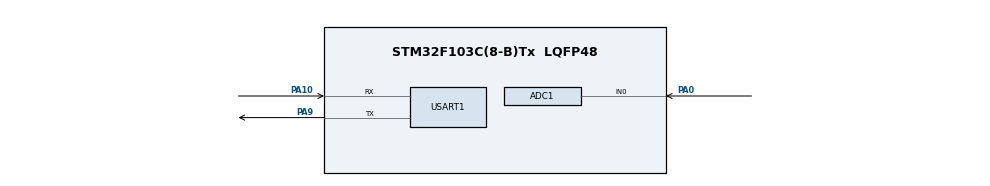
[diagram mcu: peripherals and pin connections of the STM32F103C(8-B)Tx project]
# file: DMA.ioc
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ADC1.Channel-0\#ChannelRegularConversion=ADC_CHANNEL_0
ADC1.ExternalTrigConv=ADC_EXTERNALTRIGCONV_T3_TRGO
ADC1.NbrOfConversionFlag=1
ADC1.Rank-0\#ChannelRegularConversion=1
ADC1.SamplingTime-0\#ChannelRegularConversion=ADC_SAMPLETIME_55CYCLES_5
ADC1.master=1
Dma.ADC1.0.Direction=DMA_PERIPH_TO_MEMORY
Dma.ADC1.0.Instance=DMA1_Channel1
Dma.ADC1.0.MemDataAlignment=DMA_MDATAALIGN_HALFWORD
Dma.ADC1.0.MemInc=DMA_MINC_ENABLE
Dma.ADC1.0.Mode=DMA_CIRCULAR
Dma.ADC1.0.PeriphDataAlignment=DMA_PDATAALIGN_HALFWORD
Dma.ADC1.0.PeriphInc=DMA_PINC_DISABLE
Dma.ADC1.0.Priority=DMA_PRIORITY_LOW
Dma.Request0=ADC1
Mcu.Family=STM32F1
Mcu.Name=STM32F103C(8-B)Tx
Mcu.Package=LQFP48
NVIC.DMA1_Channel1_IRQn=true\:0\:0\:false\:false\:true\:false\:true\:true
NVIC.PriorityGroup=NVIC_PRIORITYGROUP_4
PA0-WKUP.Signal=ADCx_IN0
PA10.Mode=Asynchronous
PA10.Signal=USART1_RX
PA13.Mode=Serial_Wire
PA13.Signal=SYS_JTMS-SWDIO
PA14.Mode=Serial_Wire
PA14.Signal=SYS_JTCK-SWCLK
PA9.Mode=Asynchronous
PA9.Signal=USART1_TX
ProjectManager.HeapSize=0x200
ProjectManager.StackSize=0x400
ProjectManager.TargetToolchain=CMake
RCC.APB1Freq_Value=8000000
RCC.APB2Freq_Value=8000000
SH.ADCx_IN0.0=ADC1_IN0,IN0
TIM3.Period=99
TIM3.Prescaler=799
TIM3.TIM_MasterOutputTrigger=TIM_TRGO_UPDATE
USART1.VirtualMode=VM_ASYNC
VP_TIM3_VS_ClockSourceINT.Mode=Internal
board=custom

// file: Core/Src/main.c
/* USER CODE BEGIN Header */
/**
  ******************************************************************************
  * @file           : main.c
  * @brief          : Main program body
  ******************************************************************************
  * @attention
  *
  * Copyright (c) 2026 STMicroelectronics.
  * All rights reserved.
  *
  * This software is licensed under terms that can be found in the LICENSE file
  * in the root directory of this software component.
  * If no LICENSE file comes with this software, it is provided AS-IS.
  *
  ******************************************************************************
  */
/* USER CODE END Header */
#include "main.h"

/* USER CODE BEGIN Includes */
#include <stdio.h>
/* USER CODE END Includes */

ADC_HandleTypeDef hadc1;
DMA_HandleTypeDef hdma_adc1;

TIM_HandleTypeDef htim3;

UART_HandleTypeDef huart1;

/* USER CODE BEGIN PV */

uint16_t adc_buffer[16];

// 前 8 个数据已经采集完成
volatile uint8_t dma_half_ready = 0;

// 后 8 个数据已经采集完成
volatile uint8_t dma_full_ready = 0;

// volatile 是 C 语言中的关键字。
// 它在这里的作用是告诉编译器：
// 这个变量可能被中断处理流程修改，主程序读取它时，应保留实际的内存访问。
// 因为这个变量会在 DMA 完成回调中被修改，而主循环需要读取它。
// 注意，volatile 不代表线程安全，也不能保证复杂的共享数据操作一定正确。这一点进入 FreeRTOS 后我们还会学习。

/* USER CODE END PV */

void SystemClock_Config(void);
static void MX_GPIO_Init(void);
static void MX_DMA_Init(void);
static void MX_ADC1_Init(void);
static void MX_TIM3_Init(void);
static void MX_USART1_UART_Init(void);

int main(void)
{

  /* MCU Configuration--------------------------------------------------------*/

  /* Reset of all peripherals, Initializes the Flash interface and the Systick. */
  HAL_Init();

  /* Configure the system clock */
  SystemClock_Config();

  /* Initialize all configured peripherals */
  MX_GPIO_Init();
  MX_DMA_Init();
  MX_ADC1_Init();
  MX_TIM3_Init();
  MX_USART1_UART_Init();
  /* USER CODE BEGIN 2 */

  // 1. ADC 校准
  if (HAL_ADCEx_Calibration_Start(&hadc1) != HAL_OK)
  {
      Error_Handler();
  }

  // 2. 启动 ADC + DMA
  if (HAL_ADC_Start_DMA(&hadc1, (uint32_t *)adc_buffer, 16) != HAL_OK)
  {
      Error_Handler();
  }

  // 3. 启动 TIM3
  if (HAL_TIM_Base_Start(&htim3) != HAL_OK)
  {
      Error_Handler();
  }

  /* USER CODE END 2 */

  /* Infinite loop */
  while (1)
  {

  /* USER CODE BEGIN 3 */

    if (dma_half_ready || dma_full_ready)
    {
        uint8_t start;

        // 判断哪一半数据已经准备好
        if (dma_half_ready)
        {
            dma_half_ready = 0;
            start = 0;
        }
        else
        {
            dma_full_ready = 0;
            start = 8;
        }

        // 计算这一半数据的平均值
        uint32_t sum = 0;

        for (uint8_t i = start; i < start + 8; i++)
        {
            sum += adc_buffer[i];
        }

        uint32_t average = sum / 8;

        // 串口输出
        char uart_buf[64];

        int len = snprintf(
            uart_buf,
            sizeof(uart_buf),
            "DMA[%u-%u] Average = %lu\r\n",
            (unsigned int)start,
            (unsigned int)(start + 7),
            (unsigned long)average
        );

        if (len > 0 && len < (int)sizeof(uart_buf))
        {
            HAL_UART_Transmit(
                &huart1,
                (uint8_t *)uart_buf,
                (uint16_t)len,
                1000
            );
        }
    }
  }
  /* USER CODE END 3 */
}

void SystemClock_Config(void)
{
  RCC_OscInitTypeDef RCC_OscInitStruct = {0};
  RCC_ClkInitTypeDef RCC_ClkInitStruct = {0};
  RCC_PeriphCLKInitTypeDef PeriphClkInit = {0};

  /** Initializes the RCC Oscillators according to the specified parameters
  * in the RCC_OscInitTypeDef structure.
  */
  RCC_OscInitStruct.OscillatorType = RCC_OSCILLATORTYPE_HSI;
  RCC_OscInitStruct.HSIState = RCC_HSI_ON;
  RCC_OscInitStruct.HSICalibrationValue = RCC_HSICALIBRATION_DEFAULT;
  RCC_OscInitStruct.PLL.PLLState = RCC_PLL_NONE;
  if (HAL_RCC_OscConfig(&RCC_OscInitStruct) != HAL_OK)
  {
    Error_Handler();
  }

  /** Initializes the CPU, AHB and APB buses clocks
  */
  RCC_ClkInitStruct.ClockType = RCC_CLOCKTYPE_HCLK|RCC_CLOCKTYPE_SYSCLK
                              |RCC_CLOCKTYPE_PCLK1|RCC_CLOCKTYPE_PCLK2;
  RCC_ClkInitStruct.SYSCLKSource = RCC_SYSCLKSOURCE_HSI;
  RCC_ClkInitStruct.AHBCLKDivider = RCC_SYSCLK_DIV1;
  RCC_ClkInitStruct.APB1CLKDivider = RCC_HCLK_DIV1;
  RCC_ClkInitStruct.APB2CLKDivider = RCC_HCLK_DIV1;

  if (HAL_RCC_ClockConfig(&RCC_ClkInitStruct, FLASH_LATENCY_0) != HAL_OK)
  {
    Error_Handler();
  }
  PeriphClkInit.PeriphClockSelection = RCC_PERIPHCLK_ADC;
  PeriphClkInit.AdcClockSelection = RCC_ADCPCLK2_DIV2;
  if (HAL_RCCEx_PeriphCLKConfig(&PeriphClkInit) != HAL_OK)
  {
    Error_Handler();
  }
}

static void MX_ADC1_Init(void)
{

  ADC_ChannelConfTypeDef sConfig = {0};

  /** Common config
  */
  hadc1.Instance = ADC1;
  hadc1.Init.ScanConvMode = ADC_SCAN_DISABLE;
  hadc1.Init.ContinuousConvMode = DISABLE;
  hadc1.Init.DiscontinuousConvMode = DISABLE;
  hadc1.Init.ExternalTrigConv = ADC_EXTERNALTRIGCONV_T3_TRGO;
  hadc1.Init.DataAlign = ADC_DATAALIGN_RIGHT;
  hadc1.Init.NbrOfConversion = 1;
  if (HAL_ADC_Init(&hadc1) != HAL_OK)
  {
    Error_Handler();
  }

  /** Configure Regular Channel
  */
  sConfig.Channel = ADC_CHANNEL_0;
  sConfig.Rank = ADC_REGULAR_RANK_1;
  sConfig.SamplingTime = ADC_SAMPLETIME_55CYCLES_5;
  if (HAL_ADC_ConfigChannel(&hadc1, &sConfig) != HAL_OK)
  {
    Error_Handler();
  }

}

static void MX_TIM3_Init(void)
{

  TIM_ClockConfigTypeDef sClockSourceConfig = {0};
  TIM_MasterConfigTypeDef sMasterConfig = {0};

  htim3.Instance = TIM3;
  htim3.Init.Prescaler = 799;
  htim3.Init.CounterMode = TIM_COUNTERMODE_UP;
  htim3.Init.Period = 99;
  htim3.Init.ClockDivision = TIM_CLOCKDIVISION_DIV1;
  htim3.Init.AutoReloadPreload = TIM_AUTORELOAD_PRELOAD_DISABLE;
  if (HAL_TIM_Base_Init(&htim3) != HAL_OK)
  {
    Error_Handler();
  }
  sClockSourceConfig.ClockSource = TIM_CLOCKSOURCE_INTERNAL;
  if (HAL_TIM_ConfigClockSource(&htim3, &sClockSourceConfig) != HAL_OK)
  {
    Error_Handler();
  }
  sMasterConfig.MasterOutputTrigger = TIM_TRGO_UPDATE;
  sMasterConfig.MasterSlaveMode = TIM_MASTERSLAVEMODE_DISABLE;
  if (HAL_TIMEx_MasterConfigSynchronization(&htim3, &sMasterConfig) != HAL_OK)
  {
    Error_Handler();
  }

}

static void MX_USART1_UART_Init(void)
{

  huart1.Instance = USART1;
  huart1.Init.BaudRate = 115200;
  huart1.Init.WordLength = UART_WORDLENGTH_8B;
  huart1.Init.StopBits = UART_STOPBITS_1;
  huart1.Init.Parity = UART_PARITY_NONE;
  huart1.Init.Mode = UART_MODE_TX_RX;
  huart1.Init.HwFlowCtl = UART_HWCONTROL_NONE;
  huart1.Init.OverSampling = UART_OVERSAMPLING_16;
  if (HAL_UART_Init(&huart1) != HAL_OK)
  {
    Error_Handler();
  }

}

static void MX_DMA_Init(void)
{

  /* DMA controller clock enable */
  __HAL_RCC_DMA1_CLK_ENABLE();

  /* DMA interrupt init */
  /* DMA1_Channel1_IRQn interrupt configuration */
  HAL_NVIC_SetPriority(DMA1_Channel1_IRQn, 0, 0);
  HAL_NVIC_EnableIRQ(DMA1_Channel1_IRQn);

}

static void MX_GPIO_Init(void)
{

  /* GPIO Ports Clock Enable */
  __HAL_RCC_GPIOA_CLK_ENABLE();

}

/* USER CODE BEGIN 4 */

// DMA 半传输完成回调
void HAL_ADC_ConvHalfCpltCallback(ADC_HandleTypeDef *hadc)
{
    if (hadc->Instance == ADC1)
    {
        dma_half_ready = 1;
    }
}

// DMA 全部传输完成回调
void HAL_ADC_ConvCpltCallback(ADC_HandleTypeDef *hadc)
{
    if (hadc->Instance == ADC1)
    {
        dma_full_ready = 1;
    }
}

/* USER CODE END 4 */

void Error_Handler(void)
{
  __disable_irq();
  while (1)
  {
  }
}
